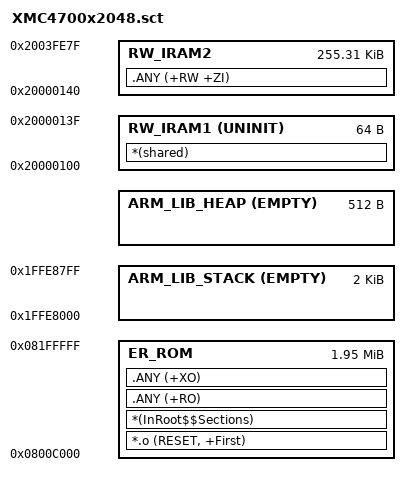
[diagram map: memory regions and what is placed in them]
#! armcc -E
; command above MUST be in first line (no comment above!)

; *************************************************************
; *** Scatter-Loading Description File generated by uVision ***
; *************************************************************
;*********************************************************************************************************************
;* @file     XMC4700x2048_ac5.sct
;* @brief    Scatter-Loading Description File for Infineon XMC4700 2048K Flash Devices
;* @version  V1.0
;* @date     26 Jan 2021
;*
;* @cond
;*********************************************************************************************************************
;* Copyright (c) 2018-2020, Infineon Technologies AG
;* All rights reserved.                        
;*                                             
;* Boost Software License - Version 1.0 - August 17th, 2003
;* 
;* Permission is hereby granted, free of charge, to any person or organization
;* obtaining a copy of the software and accompanying documentation covered by
;* this license (the "Software") to use, reproduce, display, distribute,
;* execute, and transmit the Software, and to prepare derivative works of the
;* Software, and to permit third-parties to whom the Software is furnished to
;* do so, all subject to the following:
;* 
;* The copyright notices in the Software and this entire statement, including
;* the above license grant, this restriction and the following disclaimer,
;* must be included in all copies of the Software, in whole or in part, and
;* all derivative works of the Software, unless such copies or derivative
;* works are solely in the form of machine-executable object code generated by
;* a source language processor.
;* 
;* THE SOFTWARE IS PROVIDED "AS IS", WITHOUT WARRANTY OF ANY KIND, EXPRESS OR
;* IMPLIED, INCLUDING BUT NOT LIMITED TO THE WARRANTIES OF MERCHANTABILITY,
;* FITNESS FOR A PARTICULAR PURPOSE, TITLE AND NON-INFRINGEMENT. IN NO EVENT
;* SHALL THE COPYRIGHT HOLDERS OR ANYONE DISTRIBUTING THE SOFTWARE BE LIABLE
;* FOR ANY DAMAGES OR OTHER LIABILITY, WHETHER IN CONTRACT, TORT OR OTHERWISE,
;* ARISING FROM, OUT OF OR IN CONNECTION WITH THE SOFTWARE OR THE USE OR OTHER
;* DEALINGS IN THE SOFTWARE.
;*                                                                              
;* To improve the quality of the software, users are encouraged to share 
;* modifications, enhancements or bug fixes with Infineon Technologies AG 
;* at XMCSupport@infineon.com.
;*********************************************************************************************************************
;*
;**************************** Change history ********************************
;* V1.0, Jan, 26, 2021 JFT:Initial version
;*
;* @endcond 
;*

/*
;-------- <<< Use Configuration Wizard in Context Menu >>> -------------------
*/

/*--------------------- Stack / Heap Configuration ---------------------------
; <h> Stack / Heap Configuration
;   <o0> Stack Size (in Bytes) <0x0-0xFFFFFFFF:8>
;   <o1> Heap Size (in Bytes) <0x0-0xFFFFFFFF:8>
; </h>
 *----------------------------------------------------------------------------*/
#define __STACK_SIZE       0x00000800
#define __HEAP_SIZE        0x00000200

/*
;------------- <<< end of configuration section >>> ---------------------------
*/

#define __ROM_BASE     0x0800C000
#define __ROM_SIZE     0x001F4000

#define __PSRAM_BASE   0x1FFE8000
#define __PSRAM_SIZE   0x00018000

; Theoretically it should also be possible to place the shared parameters buffer at
; 0x20000000. Testing shows  though, that the first few bytes are still changed when
; the user program performs a software reset. Therefore it was moved forward by 0x100.
#define __DSRAM1_BASE  0x20000100
#define __DSRAM1_SIZE  0x00000040

#define __DSRAM2_BASE  0x20000140
#define __DSRAM2_SIZE  0x0001FEC0

#define __DSRAM3_BASE  0x20020000
#define __DSRAM3_SIZE  0x0000D000

/*----------------------------------------------------------------------------
  User Stack & Heap boundery definition
 *----------------------------------------------------------------------------*/
#define __STACK_TOP        (__PSRAM_BASE + __STACK_SIZE)
#define __HEAP_BASE        (AlignExpr(__PSRAM_BASE + __STACK_SIZE + __HEAP_SIZE, 8))

/*----------------------------------------------------------------------------
  Scatter File Definitions definition
 *----------------------------------------------------------------------------*/
#define __RO_BASE         __ROM_BASE
#define __RO_SIZE         __ROM_SIZE

#define __NO_INIT         64

LR_ROM __RO_BASE __RO_SIZE  {                       ; load region size_region
  ER_ROM __RO_BASE __RO_SIZE  {                     ; load address = execution address
   *.o (RESET, +First)
   *(InRoot$$Sections)
   .ANY (+RO)
   .ANY (+XO)
  }

  ARM_LIB_STACK __STACK_TOP EMPTY -__STACK_SIZE {   ; Reserve empty region for stack
  }

#if __HEAP_SIZE > 0
  ARM_LIB_HEAP  __HEAP_BASE EMPTY  __HEAP_SIZE  {   ; Reserve empty region for heap
  }
#endif

/*----------------------------------------------------------------------------
  PSRAM +0 (__PSRAM_SIZE - __STACK_SIZE - __HEAP_SIZE)  {
   program1.o (+RW +ZI)
  }
 *----------------------------------------------------------------------------*/

  RW_IRAM1 __DSRAM1_BASE UNINIT __DSRAM1_SIZE  {  ; no init for shared params
   *(shared)
  }

  RW_IRAM2 __DSRAM2_BASE (__DSRAM2_SIZE + __DSRAM2_SIZE - __NO_INIT)  {
   .ANY (+RW +ZI)
  }

/*----------------------------------------------------------------------------
  RW_IRAM3 __DSRAM3_BASE (__DSRAM3_SIZE)  {
   program2.o (+RW +ZI)
  }
 *----------------------------------------------------------------------------*/
}

